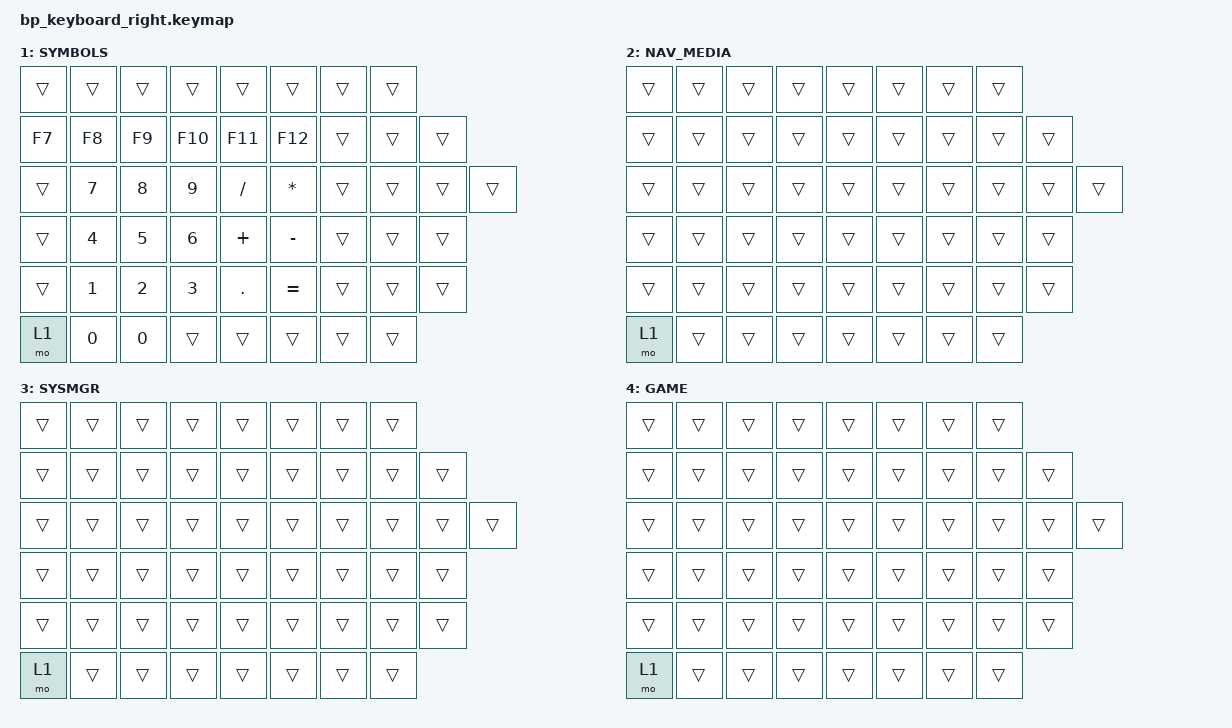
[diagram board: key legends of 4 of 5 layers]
/*
 * Copyright (c) 2026 BP Keyboard
 * SPDX-License-Identifier: MIT
 */

#include <behaviors.dtsi>
#include <dt-bindings/zmk/keys.h>
#include <dt-bindings/zmk/bt.h>
#include <dt-bindings/zmk/outputs.h>

/ {
    keymap {
        compatible = "zmk,keymap";

        // 基础层 - BASE
        default_layer {
            display-name = "BASE";
            bindings = <
// ─────────────────────────────────── 行0 (顶部功能行) 8键 ───────────────────────────────────
//   +-----+ +-----+ +-----+ +-----+ +-----+ +-----+ +-----+ +------+
//   | F6  | | F7  | | F8  | | F9  | | F10 | | F11 | | F12 | | PSCR |
//   +-----+ +-----+ +-----+ +-----+ +-----+ +-----+ +-----+ +------+
    &kp F6      &kp F7      &kp F8      &kp F9      &kp F10     &kp F11     &kp F12     &kp PSCRN
// ─────────────────────────────────── 行1 (数字行) 9键 ───────────────────────────────────
//   +-----+ +-----+ +-----+ +-----+ +-----+ +-----+ +-----+ +-------------+ +-----+
//   |  ^  | |  &  | |  *  | |  (  | |  )  | |  _  | |  +  | |     BSPC    | | Del |
//   |  6  | |  7  | |  8  | |  9  | |  0  | |  -  | |  =  | |             | |     |
//   +-----+ +-----+ +-----+ +-----+ +-----+ +-----+ +-----+ +-------------+ +-----+
    &kp N6      &kp N7      &kp N8      &kp N9      &kp N0      &kp MINUS   &kp EQUAL   &kp BSPC    &kp DEL
// ─────────────────────────────────── 行2 (Tab行) 10键 (含额外方向键上) ───────────────────────────────────
//   +-----+ +-----+ +-----+ +-----+ +-----+ +-----+ +-----+ +-----+ +-------+ +-----+
//   |  T  | |  Y  | |  U  | |  I  | |  O  | |  P  | |  {  | |  }  | |   |   | | Ins |
//   |     | |     | |     | |     | |     | |     | |  [  | |  ]  | |   \   | |     |
//   +-----+ +-----+ +-----+ +-----+ +-----+ +-----+ +-----+ +-----+ +-------+ +-----+
//                                                                                 ↑ (额外键 RC(4,10))
    &kp T       &kp Y       &kp U       &kp I       &kp O       &kp P       &kp LBKT    &kp RBKT    &kp BSLH    &kp INS     &kp UP
// ─────────────────────────────────── 行3 (Caps行) 9键 ───────────────────────────────────
//   +-----+ +-----+ +-----+ +-----+ +-----+ +-----+ +-----+ +-------------+ +-----+
//   |  G  | |  H  | |  J  | |  K  | |  L  | |  :  | |  "  | |     ENT     | |Home |
//   |     | |     | |     | |     | |     | |  ;  | |  '  | |             | |     |
//   +-----+ +-----+ +-----+ +-----+ +-----+ +-----+ +-----+ +-------------+ +-----+
    &kp G       &kp H       &kp J       &kp K       &kp L       &kp SEMI    &kp SQT     &kp RET     &kp HOME
// ─────────────────────────────────── 行4 (Shift行) 9键 ───────────────────────────────────
//   +-----+ +-----+ +-----+ +-----+ +-----+ +-----+ +-----------+ +-----+ +-----+
//   |  B  | |  N  | |  M  | |  <  | |  >  | |  ?  | |   Shift   | |  ↑  | | End |
//   |     | |     | |     | |  ,  | |  .  | |  /  | |           | |     | |     |
//   +-----+ +-----+ +-----+ +-----+ +-----+ +-----+ +-----------+ +-----+ +-----+
    &kp B       &kp N       &kp M       &kp COMMA   &kp DOT     &kp FSLH    &kp LSHFT   &kp UP      &kp END
// ─────────────────────────────────── 行5 (拇指区) 7键 ───────────────────────────────────
//   +-----+       +-------+ +-------+ +-------+ +-------+ +-----+ +-----+ +-----+
//   | MO1 |       | Space | | Space | | AltGr | | Ctrl  | |  ←  | |  ↓  | |  →  |
//   +-----+       +-------+ +-------+ +-------+ +-------+ +-----+ +-----+ +-----+
    &mo 1       &kp SPACE   &kp SPACE   &kp RALT    &kp RCTRL   &kp LEFT    &kp DOWN    &kp RIGHT
            >;
        };

        // 符号/数字层 - SYMBOLS (MO1)
        sym_layer {
            display-name = "SYMBOLS";
            bindings = <
// ─────────────────────────────────── 行0 (顶部) 全透传 ───────────────────────────────────
    &trans      &trans      &trans      &trans      &trans      &trans      &trans      &trans
// ─────────────────────────────────── 行1 (数字行) 9键 ───────────────────────────────────
//   +-----+ +-----+ +-----+ +-----+ +-----+ +-----+ +-----+ +-------------+ +-----+
//   | F7  | | F8  | | F9  | | F10 | | F11 | | F12 | | --- | |     ---     | | --- |
//   +-----+ +-----+ +-----+ +-----+ +-----+ +-----+ +-----+ +-------------+ +-----+
    &kp F7      &kp F8      &kp F9      &kp F10     &kp F11     &kp F12     &trans      &trans      &trans
// ─────────────────────────────────── 行2 (Tab行) 10键 ───────────────────────────────────
//   +-----+ +-----+ +-----+ +-----+ +-----+ +-----+ +-----+ +-----+ +-------+ +-----+
//   | --- | |  7  | |  8  | |  9  | |  /  | |  *  | | --- | | --- | |  ---  | | --- |
//   +-----+ +-----+ +-----+ +-----+ +-----+ +-----+ +-----+ +-----+ +-------+ +-----+
    &trans      &kp N7      &kp N8      &kp N9      &kp FSLH    &kp ASTRK   &trans      &trans      &trans      &trans
// ─────────────────────────────────── 行3 (Caps行) 9键 ───────────────────────────────────
//   +-----+ +-----+ +-----+ +-----+ +-----+ +-----+ +-----+ +-------------+ +-----+
//   | --- | |  4  | |  5  | |  6  | |  +  | |  -  | | --- | |     ---     | | --- |
//   +-----+ +-----+ +-----+ +-----+ +-----+ +-----+ +-----+ +-------------+ +-----+
    &trans      &kp N4      &kp N5      &kp N6      &kp PLUS    &kp MINUS   &trans      &trans      &trans
// ─────────────────────────────────── 行4 (Shift行) 9键 ───────────────────────────────────
//   +-----+ +-----+ +-----+ +-----+ +-----+ +-----+ +-----------+ +-----+ +-----+
//   | --- | |  1  | |  2  | |  3  | |  .  | |  =  | |    ---    | | --- | | --- |
//   +-----+ +-----+ +-----+ +-----+ +-----+ +-----+ +-----------+ +-----+ +-----+
    &trans      &kp N1      &kp N2      &kp N3      &kp DOT     &kp EQUAL   &trans      &trans      &trans
// ─────────────────────────────────── 行5 (拇指区) 7键 ───────────────────────────────────
    &mo 1       &kp N0      &kp N0      &trans      &trans      &trans      &trans      &trans
            >;
        };

        // 导航/媒体层 - NAV_MEDIA (MO2) 全透传
        nav_layer {
            display-name = "NAV_MEDIA";
            bindings = <
    &trans      &trans      &trans      &trans      &trans      &trans      &trans      &trans
    &trans      &trans      &trans      &trans      &trans      &trans      &trans      &trans      &trans
    &trans      &trans      &trans      &trans      &trans      &trans      &trans      &trans      &trans      &trans
    &trans      &trans      &trans      &trans      &trans      &trans      &trans      &trans      &trans
    &trans      &trans      &trans      &trans      &trans      &trans      &trans      &trans      &trans
    &mo 1       &trans      &trans      &trans      &trans      &trans      &trans      &trans
            >;
        };

        // 系统管理层 - SYSMGR (MO1+MO2) 全透传
        sys_layer {
            display-name = "SYSMGR";
            bindings = <
    &trans      &trans      &trans      &trans      &trans      &trans      &trans      &trans
    &trans      &trans      &trans      &trans      &trans      &trans      &trans      &trans      &trans
    &trans      &trans      &trans      &trans      &trans      &trans      &trans      &trans      &trans      &trans
    &trans      &trans      &trans      &trans      &trans      &trans      &trans      &trans      &trans
    &trans      &trans      &trans      &trans      &trans      &trans      &trans      &trans      &trans
    &mo 1       &trans      &trans      &trans      &trans      &trans      &trans      &trans
            >;
        };

        // 游戏层 - GAME (TG4) 全透传
        game_layer {
            display-name = "GAME";
            bindings = <
    &trans      &trans      &trans      &trans      &trans      &trans      &trans      &trans
    &trans      &trans      &trans      &trans      &trans      &trans      &trans      &trans      &trans
    &trans      &trans      &trans      &trans      &trans      &trans      &trans      &trans      &trans      &trans
    &trans      &trans      &trans      &trans      &trans      &trans      &trans      &trans      &trans
    &trans      &trans      &trans      &trans      &trans      &trans      &trans      &trans      &trans
    &mo 1       &trans      &trans      &trans      &trans      &trans      &trans      &trans
            >;
        };
    };
};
